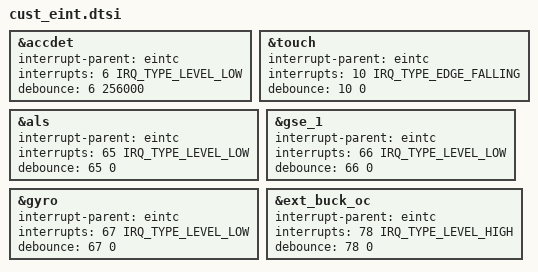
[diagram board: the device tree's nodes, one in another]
/*
 * Generated by MTK SP Drv_CodeGen Version 03.13.6	for MT6753. Copyright MediaTek Inc. (C) 2013.
 * Wed Jan 11 12:19:51 2017
 * Do Not Modify the File.
 */

#include <dt-bindings/interrupt-controller/irq.h>
#include <dt-bindings/interrupt-controller/arm-gic.h>

/*************************
 * EINT DTSI File
*************************/

&accdet {
	interrupt-parent = <&eintc>;
	interrupts = <6 IRQ_TYPE_LEVEL_LOW>;
	debounce = <6 256000>;
	status = "okay";
};
&touch {
	interrupt-parent = <&eintc>;
	interrupts = <10 IRQ_TYPE_EDGE_FALLING>;
	debounce = <10 0>;
	status = "okay";
};
&als {
	interrupt-parent = <&eintc>;
	interrupts = <65 IRQ_TYPE_LEVEL_LOW>;
	debounce = <65 0>;
	status = "okay";
};
&gse_1 {
	interrupt-parent = <&eintc>;
	interrupts = <66 IRQ_TYPE_LEVEL_LOW>;
	debounce = <66 0>;
	status = "okay";
};
&gyro {
	interrupt-parent = <&eintc>;
	interrupts = <67 IRQ_TYPE_LEVEL_LOW>;
	debounce = <67 0>;
	status = "okay";
};
&ext_buck_oc {
	interrupt-parent = <&eintc>;
	interrupts = <78 IRQ_TYPE_LEVEL_HIGH>;
	debounce = <78 0>;
	status = "okay";
};
